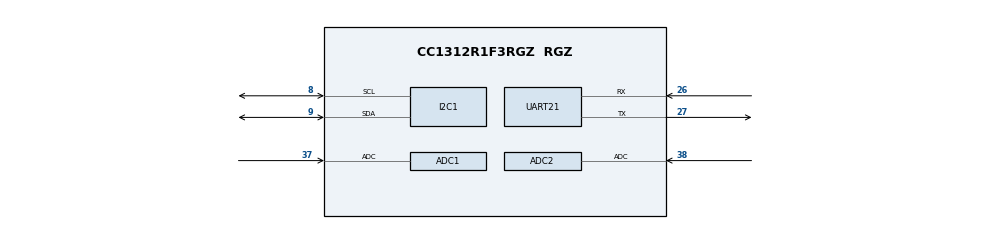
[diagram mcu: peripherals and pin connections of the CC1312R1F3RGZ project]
/**
 * @cliArgs --device "CC1312R1F3RGZ" --package "RGZ" --part "Default" --product "simplelink_cc13x2_26x2_sdk@5.20.00.52"
 * @versions {"data":"2021060817","timestamp":"2021060817","tool":"1.8.2+1992","templates":null}
 */

/**
 * Import the modules used in this configuration.
 */
const CCFG      = scripting.addModule("/ti/devices/CCFG");
const rfdesign  = scripting.addModule("/ti/devices/radioconfig/rfdesign");
const ADC       = scripting.addModule("/ti/drivers/ADC", {}, false);
const ADC1      = ADC.addInstance();
const ADC2      = ADC.addInstance();
const Board     = scripting.addModule("/ti/drivers/Board");
const I2C       = scripting.addModule("/ti/drivers/I2C", {}, false);
const I2C1      = I2C.addInstance();
const NVS       = scripting.addModule("/ti/drivers/NVS", {}, false);
const NVS1      = NVS.addInstance();
const RF        = scripting.addModule("/ti/drivers/RF");
const RTOS      = scripting.addModule("/ti/drivers/RTOS");
const TRNG      = scripting.addModule("/ti/drivers/TRNG", {}, false);
const TRNG1     = TRNG.addInstance();
const UART2     = scripting.addModule("/ti/drivers/UART2", {}, false);
const UART21    = UART2.addInstance();
const Watchdog  = scripting.addModule("/ti/drivers/Watchdog", {}, false);
const Watchdog1 = Watchdog.addInstance();
const easylink  = scripting.addModule("/ti/easylink/easylink");

/**
 * Write custom configuration values to the imported modules.
 */
CCFG.enableBootloaderBackdoor = true;
CCFG.dioBootloaderBackdoor    = 13;
CCFG.levelBootloaderBackdoor  = "Active low";
CCFG.ccfgTemplate.$name       = "ti_devices_CCFGTemplate0";

ADC1.$name                = "CONFIG_ADC_0";
ADC1.adc.adcPin.$assign   = "37";
ADC1.adcPinInstance.$name = "CONFIG_PIN_0";

ADC2.$name                = "CONFIG_ADC_1";
ADC2.adc.adcPin.$assign   = "38";
ADC2.adcPinInstance.$name = "CONFIG_PIN_1";

Board.generateInitializationFunctions = false;

I2C1.$name                = "CONFIG_I2C_0";
I2C1.i2c.sdaPin.$assign   = "9";
I2C1.i2c.sclPin.$assign   = "8";
I2C1.sdaPinInstance.$name = "CONFIG_PIN_4";
I2C1.clkPinInstance.$name = "CONFIG_PIN_5";

NVS1.$name               = "CONFIG_NVS_0";
NVS1.internalFlash.$name = "ti_drivers_nvs_NVSCC26XX0";

TRNG1.$name = "CONFIG_TRNG_0";

UART21.$name               = "CONFIG_UART2_0";
UART21.uart.txPin.$assign  = "27";
UART21.uart.rxPin.$assign  = "26";
UART21.txPinInstance.$name = "CONFIG_PIN_2";
UART21.rxPinInstance.$name = "CONFIG_PIN_3";

Watchdog1.$name = "CONFIG_WATCHDOG_0";

easylink.addrSize                                               = 8;
easylink.EasyLink_Phy_5kbpsSlLr                                 = true;
easylink.EasyLink_Phy_Custom                                    = false;
easylink.radioConfigEasylinkPhy5kbpssllr.codeExportConfig.$name = "ti_devices_radioconfig_code_export_param1";

/**
 * Pinmux solution for unlocked pins/peripherals. This ensures that minor changes to the automatic solver in a future
 * version of the tool will not impact the pinmux you originally saw.  These lines can be completely deleted in order to
 * re-solve from scratch.
 */
ADC1.adc.$suggestSolution           = "ADC0";
ADC2.adc.$suggestSolution           = "ADC0";
I2C1.i2c.$suggestSolution           = "I2C0";
UART21.uart.$suggestSolution        = "UART0";
Watchdog1.watchdog.$suggestSolution = "WDT0";
